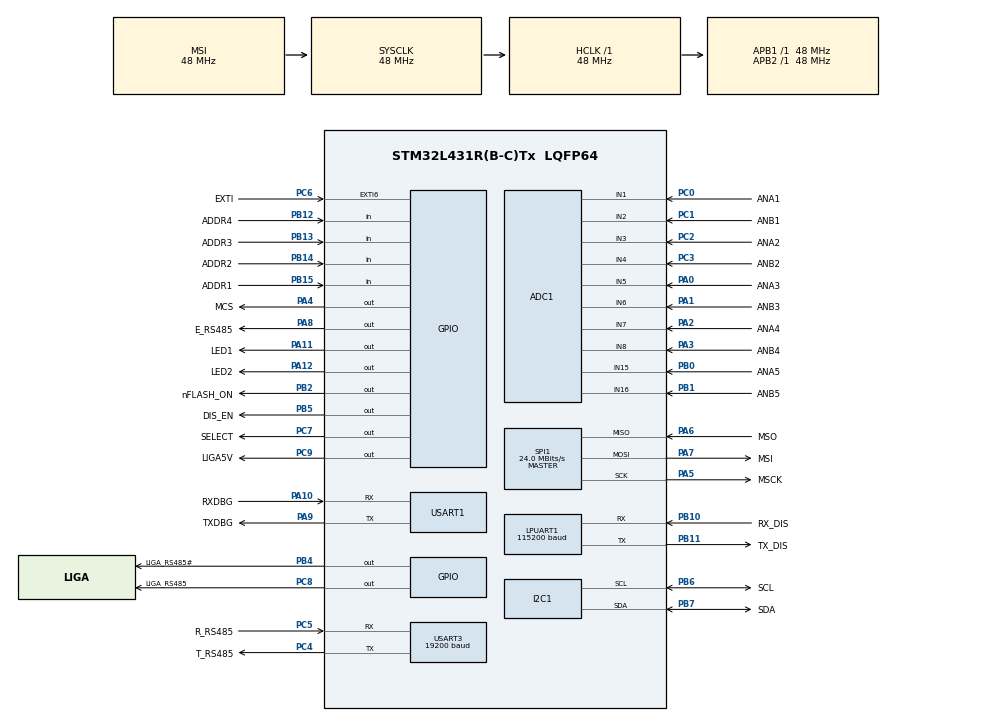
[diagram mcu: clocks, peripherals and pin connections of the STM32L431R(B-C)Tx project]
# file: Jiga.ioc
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ADC1.Channel-0\#ChannelRegularConversion=ADC_CHANNEL_16
ADC1.Channel-1\#ChannelRegularConversion=ADC_CHANNEL_15
ADC1.Channel-2\#ChannelRegularConversion=ADC_CHANNEL_8
ADC1.Channel-3\#ChannelRegularConversion=ADC_CHANNEL_7
ADC1.Channel-4\#ChannelRegularConversion=ADC_CHANNEL_6
ADC1.Channel-5\#ChannelRegularConversion=ADC_CHANNEL_5
ADC1.Channel-6\#ChannelRegularConversion=ADC_CHANNEL_4
ADC1.Channel-7\#ChannelRegularConversion=ADC_CHANNEL_3
ADC1.Channel-8\#ChannelRegularConversion=ADC_CHANNEL_2
ADC1.Channel-9\#ChannelRegularConversion=ADC_CHANNEL_1
ADC1.NbrOfConversion=10
ADC1.NbrOfConversionFlag=1
ADC1.OffsetNumber-0\#ChannelRegularConversion=ADC_OFFSET_NONE
ADC1.OffsetNumber-1\#ChannelRegularConversion=ADC_OFFSET_NONE
ADC1.OffsetNumber-2\#ChannelRegularConversion=ADC_OFFSET_NONE
ADC1.OffsetNumber-3\#ChannelRegularConversion=ADC_OFFSET_NONE
ADC1.OffsetNumber-4\#ChannelRegularConversion=ADC_OFFSET_NONE
ADC1.OffsetNumber-5\#ChannelRegularConversion=ADC_OFFSET_NONE
ADC1.OffsetNumber-6\#ChannelRegularConversion=ADC_OFFSET_NONE
ADC1.OffsetNumber-7\#ChannelRegularConversion=ADC_OFFSET_NONE
ADC1.OffsetNumber-8\#ChannelRegularConversion=ADC_OFFSET_NONE
ADC1.OffsetNumber-9\#ChannelRegularConversion=ADC_OFFSET_NONE
ADC1.Rank-0\#ChannelRegularConversion=1
ADC1.Rank-1\#ChannelRegularConversion=2
ADC1.Rank-2\#ChannelRegularConversion=3
ADC1.Rank-3\#ChannelRegularConversion=4
ADC1.Rank-4\#ChannelRegularConversion=5
ADC1.Rank-5\#ChannelRegularConversion=6
ADC1.Rank-6\#ChannelRegularConversion=7
ADC1.Rank-7\#ChannelRegularConversion=8
ADC1.Rank-8\#ChannelRegularConversion=9
ADC1.Rank-9\#ChannelRegularConversion=10
ADC1.SamplingTime-0\#ChannelRegularConversion=ADC_SAMPLETIME_12CYCLES_5
ADC1.SamplingTime-1\#ChannelRegularConversion=ADC_SAMPLETIME_12CYCLES_5
ADC1.SamplingTime-2\#ChannelRegularConversion=ADC_SAMPLETIME_12CYCLES_5
ADC1.SamplingTime-3\#ChannelRegularConversion=ADC_SAMPLETIME_12CYCLES_5
ADC1.SamplingTime-4\#ChannelRegularConversion=ADC_SAMPLETIME_12CYCLES_5
ADC1.SamplingTime-5\#ChannelRegularConversion=ADC_SAMPLETIME_12CYCLES_5
ADC1.SamplingTime-6\#ChannelRegularConversion=ADC_SAMPLETIME_12CYCLES_5
ADC1.SamplingTime-7\#ChannelRegularConversion=ADC_SAMPLETIME_12CYCLES_5
ADC1.SamplingTime-8\#ChannelRegularConversion=ADC_SAMPLETIME_12CYCLES_5
ADC1.SamplingTime-9\#ChannelRegularConversion=ADC_SAMPLETIME_12CYCLES_5
ADC1.master=1
CRC.CRCLength=CRC_POLYLENGTH_16B
CRC.DefaultInitValueUse=DEFAULT_INIT_VALUE_DISABLE
CRC.DefaultPolynomialUse=DEFAULT_POLYNOMIAL_DISABLE
CRC.GeneratingPolynomial=X15+X2+X0
CRC.InitValue=65535
CRC.InputDataInversionMode=CRC_INPUTDATA_INVERSION_BYTE
CRC.OutputDataInversionMode=CRC_OUTPUTDATA_INVERSION_ENABLE
Dma.ADC1.0.Direction=DMA_PERIPH_TO_MEMORY
Dma.ADC1.0.Instance=DMA1_Channel1
Dma.ADC1.0.MemDataAlignment=DMA_MDATAALIGN_HALFWORD
Dma.ADC1.0.MemInc=DMA_MINC_ENABLE
Dma.ADC1.0.Mode=DMA_NORMAL
Dma.ADC1.0.PeriphDataAlignment=DMA_PDATAALIGN_HALFWORD
Dma.ADC1.0.PeriphInc=DMA_PINC_DISABLE
Dma.ADC1.0.Priority=DMA_PRIORITY_LOW
Dma.Request0=ADC1
I2C1.Timing=0x10805D88
IWDG.Prescaler=IWDG_PRESCALER_32
IWDG.Reload=2000
IWDG.Window=2000
LPUART1.BaudRate=115200
LPUART1.WordLength=UART_WORDLENGTH_8B
Mcu.Family=STM32L4
Mcu.Name=STM32L431R(B-C)Tx
Mcu.Package=LQFP64
NVIC.DMA1_Channel1_IRQn=true\:0\:0\:false\:false\:true\:false\:true\:true
NVIC.EXTI9_5_IRQn=true\:0\:0\:false\:false\:true\:true\:true\:true
NVIC.LPUART1_IRQn=true\:0\:0\:true\:false\:true\:true\:true\:true
NVIC.PriorityGroup=NVIC_PRIORITYGROUP_4
NVIC.RTC_WKUP_IRQn=true\:3\:0\:true\:false\:true\:true\:true\:true
NVIC.TIM6_DAC_IRQn=true\:1\:0\:true\:false\:true\:true\:true\:true
NVIC.USART1_IRQn=true\:2\:0\:true\:false\:true\:true\:true\:true
NVIC.USART3_IRQn=true\:2\:0\:true\:false\:true\:true\:true\:true
PA0.GPIO_Label=ANA3
PA0.Signal=ADCx_IN5
PA1.GPIO_Label=ANB3
PA1.Signal=ADCx_IN6
PA10.GPIO_Label=RXDBG
PA10.Mode=Asynchronous
PA10.Signal=USART1_RX
PA11.GPIO_Label=LED1
PA11.Signal=GPIO_Output
PA12.GPIO_Label=LED2
PA12.Signal=GPIO_Output
PA13\ (JTMS-SWDIO).Mode=Serial_Wire
PA13\ (JTMS-SWDIO).Signal=SYS_JTMS-SWDIO
PA14\ (JTCK-SWCLK).Mode=Serial_Wire
PA14\ (JTCK-SWCLK).Signal=SYS_JTCK-SWCLK
PA2.GPIO_Label=ANA4
PA2.Signal=ADCx_IN7
PA3.GPIO_Label=ANB4
PA3.Signal=ADCx_IN8
PA4.GPIO_Label=MCS
PA4.GPIO_PuPd=GPIO_NOPULL
PA4.Signal=GPIO_Output
PA5.GPIO_Label=MSCK
PA5.Mode=Full_Duplex_Master
PA5.Signal=SPI1_SCK
PA6.GPIO_Label=MSO
PA6.Mode=Full_Duplex_Master
PA6.Signal=SPI1_MISO
PA7.GPIO_Label=MSI
PA7.Mode=Full_Duplex_Master
PA7.Signal=SPI1_MOSI
PA8.GPIO_Label=E_RS485
PA8.Signal=GPIO_Output
PA9.GPIO_Label=TXDBG
PA9.Mode=Asynchronous
PA9.Signal=USART1_TX
PB0.GPIO_Label=ANA5
PB0.Signal=ADCx_IN15
PB1.GPIO_Label=ANB5
PB1.Signal=ADCx_IN16
PB10.GPIO_Label=RX_DIS
PB10.Mode=Asynchronous
PB10.Signal=LPUART1_RX
PB11.GPIO_Label=TX_DIS
PB11.Mode=Asynchronous
PB11.Signal=LPUART1_TX
PB12.GPIO_Label=ADDR4
PB12.Signal=GPIO_Input
PB13.GPIO_Label=ADDR3
PB13.Signal=GPIO_Input
PB14.GPIO_Label=ADDR2
PB14.Signal=GPIO_Input
PB15.GPIO_Label=ADDR1
PB15.Signal=GPIO_Input
PB2.GPIO_Label=nFLASH_ON
PB2.Signal=GPIO_Output
PB4\ (NJTRST).GPIO_Label=LIGA_RS485\#
PB4\ (NJTRST).GPIO_PuPd=GPIO_PULLUP
PB4\ (NJTRST).Signal=GPIO_Output
PB5.GPIO_Label=DIS_EN
PB5.GPIO_PuPd=GPIO_PULLDOWN
PB5.Signal=GPIO_Output
PB6.GPIO_Label=SCL
PB6.Mode=I2C
PB6.Signal=I2C1_SCL
PB7.GPIO_Label=SDA
PB7.Mode=I2C
PB7.Signal=I2C1_SDA
PC0.GPIO_Label=ANA1
PC0.Signal=ADCx_IN1
PC1.GPIO_Label=ANB1
PC1.Signal=ADCx_IN2
PC14-OSC32_IN\ (PC14).Mode=LSE-External-Oscillator
PC14-OSC32_IN\ (PC14).Signal=RCC_OSC32_IN
PC15-OSC32_OUT\ (PC15).Mode=LSE-External-Oscillator
PC15-OSC32_OUT\ (PC15).Signal=RCC_OSC32_OUT
PC2.GPIO_Label=ANA2
PC2.Signal=ADCx_IN3
PC3.GPIO_Label=ANB2
PC3.Signal=ADCx_IN4
PC4.GPIO_Label=T_RS485
PC4.GPIO_PuPd=GPIO_NOPULL
PC4.Mode=Asynchronous
PC4.Signal=USART3_TX
PC5.GPIO_Label=R_RS485
PC5.GPIO_PuPd=GPIO_NOPULL
PC5.Mode=Asynchronous
PC5.Signal=USART3_RX
PC6.GPIO_Label=EXTI
PC6.GPIO_ModeDefaultEXTI=GPIO_MODE_IT_FALLING
PC6.GPIO_PuPd=GPIO_NOPULL
PC6.Signal=GPXTI6
PC7.GPIO_Label=SELECT
PC7.Signal=GPIO_Output
PC8.GPIO_Label=LIGA_RS485
PC8.Signal=GPIO_Output
PC9.GPIO_Label=LIGA5V
PC9.Signal=GPIO_Output
PH0-OSC_IN\ (PH0).Mode=HSE-External-Oscillator
PH0-OSC_IN\ (PH0).Signal=RCC_OSC_IN
PH1-OSC_OUT\ (PH1).Mode=HSE-External-Oscillator
PH1-OSC_OUT\ (PH1).Signal=RCC_OSC_OUT
ProjectManager.HeapSize=0x200
ProjectManager.StackSize=0x400
ProjectManager.TargetToolchain=STM32CubeIDE
RCC.ADCCLockSelection=RCC_ADCCLKSOURCE_SYSCLK
RCC.ADCFreq_Value=48000000
RCC.AHBFreq_Value=48000000
RCC.APB1Freq_Value=48000000
RCC.APB1TimFreq_Value=48000000
RCC.APB2Freq_Value=48000000
RCC.APB2TimFreq_Value=48000000
RCC.CortexFreq_Value=48000000
RCC.HCLKFreq_Value=48000000
RCC.HSE_VALUE=8000000
RCC.HSI48_VALUE=48000000
RCC.HSI_VALUE=16000000
RCC.MSIClockRange=RCC_MSIRANGE_11
RCC.MSI_VALUE=48000000
RCC.PLLSAI1N=12
RCC.PLLSourceVirtual=RCC_PLLSOURCE_HSE
RCC.SYSCLKFreq_VALUE=48000000
RCC.VCOOutputFreq_Value=64000000
RTC.Format=RTC_FORMAT_BIN
RTC.WakeUpCounter-WakeUp=2000
SH.ADCx_IN1.0=ADC1_IN1,IN1-Single-Ended
SH.ADCx_IN15.0=ADC1_IN15,IN15-Single-Ended
SH.ADCx_IN16.0=ADC1_IN16,IN16-Single-Ended
SH.ADCx_IN2.0=ADC1_IN2,IN2-Single-Ended
SH.ADCx_IN3.0=ADC1_IN3,IN3-Single-Ended
SH.ADCx_IN4.0=ADC1_IN4,IN4-Single-Ended
SH.ADCx_IN5.0=ADC1_IN5,IN5-Single-Ended
SH.ADCx_IN6.0=ADC1_IN6,IN6-Single-Ended
SH.ADCx_IN7.0=ADC1_IN7,IN7-Single-Ended
SH.ADCx_IN8.0=ADC1_IN8,IN8-Single-Ended
SPI1.CalculateBaudRate=24.0 MBits/s
SPI1.DataSize=SPI_DATASIZE_8BIT
SPI1.Direction=SPI_DIRECTION_2LINES
SPI1.Mode=SPI_MODE_MASTER
SPI1.VirtualType=VM_MASTER
TIM6.AutoReloadPreload=TIM_AUTORELOAD_PRELOAD_ENABLE
TIM6.Period=999
TIM6.Prescaler=48
USART1.VirtualMode-Asynchronous=VM_ASYNC
USART3.BaudRate=19200
USART3.MSBFirstParam=ADVFEATURE_MSBFIRST_DISABLE
USART3.VirtualMode-Asynchronous=VM_ASYNC
VP_CRC_VS_CRC.Mode=CRC_Activate
VP_IWDG_VS_IWDG.Mode=IWDG_Activate
VP_RTC_VS_RTC_Activate.Mode=RTC_Enabled
VP_RTC_VS_RTC_Calendar.Mode=RTC_Calendar
VP_RTC_VS_RTC_WakeUp_intern.Mode=WakeUp
VP_TIM6_VS_ClockSourceINT.Mode=Enable_Timer
board=custom

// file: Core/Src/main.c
/* USER CODE BEGIN Header */
/**
  ******************************************************************************
  * @file           : main.c
  * @brief          : Main program body
  ******************************************************************************
  * @attention
  *
  * Copyright (c) 2025 STMicroelectronics.
  * All rights reserved.
  *
  * This software is licensed under terms that can be found in the LICENSE file
  * in the root directory of this software component.
  * If no LICENSE file comes with this software, it is provided AS-IS.
  *
  ******************************************************************************
  */
/* USER CODE END Header */
#include "main.h"
#include "adc.h"
#include "crc.h"
#include "dma.h"
#include "i2c.h"
#include "iwdg.h"
#include "usart.h"
#include "rtc.h"
#include "spi.h"
#include "tim.h"
#include "gpio.h"

/* USER CODE BEGIN Includes */
#include "app.h"
/* USER CODE END Includes */

void SystemClock_Config(void);

int main(void)
{

  /* MCU Configuration--------------------------------------------------------*/

  /* Reset of all peripherals, Initializes the Flash interface and the Systick. */
  HAL_Init();

  /* Configure the system clock */
  SystemClock_Config();

  /* Initialize all configured peripherals */
  MX_GPIO_Init();
  MX_DMA_Init();
  MX_ADC1_Init();
  MX_I2C1_Init();
  MX_LPUART1_UART_Init();
  MX_USART1_UART_Init();
  MX_USART3_UART_Init();
  MX_SPI1_Init();
  MX_TIM6_Init();
  MX_CRC_Init();
  MX_RTC_Init();
  MX_IWDG_Init();
  /* USER CODE BEGIN 2 */
  __disable_irq();
  APP_init();
  __enable_irq();
  /* USER CODE END 2 */

  /* Infinite loop */
  /* USER CODE BEGIN WHILE */
  while (1)
  {
      HAL_IWDG_Refresh(&hiwdg);
      APP_poll();
    /* USER CODE END WHILE */

  }
}

void SystemClock_Config(void)
{
  RCC_OscInitTypeDef RCC_OscInitStruct = {0};
  RCC_ClkInitTypeDef RCC_ClkInitStruct = {0};

  /** Configure the main internal regulator output voltage
  */
  if (HAL_PWREx_ControlVoltageScaling(PWR_REGULATOR_VOLTAGE_SCALE1) != HAL_OK)
  {
    Error_Handler();
  }

  /** Configure LSE Drive Capability
  */
  HAL_PWR_EnableBkUpAccess();
  __HAL_RCC_LSEDRIVE_CONFIG(RCC_LSEDRIVE_LOW);

  /** Initializes the RCC Oscillators according to the specified parameters
  * in the RCC_OscInitTypeDef structure.
  */
  RCC_OscInitStruct.OscillatorType = RCC_OSCILLATORTYPE_LSI|RCC_OSCILLATORTYPE_LSE
                              |RCC_OSCILLATORTYPE_MSI;
  RCC_OscInitStruct.LSEState = RCC_LSE_ON;
  RCC_OscInitStruct.LSIState = RCC_LSI_ON;
  RCC_OscInitStruct.MSIState = RCC_MSI_ON;
  RCC_OscInitStruct.MSICalibrationValue = 0;
  RCC_OscInitStruct.MSIClockRange = RCC_MSIRANGE_11;
  RCC_OscInitStruct.PLL.PLLState = RCC_PLL_NONE;
  if (HAL_RCC_OscConfig(&RCC_OscInitStruct) != HAL_OK)
  {
    Error_Handler();
  }

  /** Initializes the CPU, AHB and APB buses clocks
  */
  RCC_ClkInitStruct.ClockType = RCC_CLOCKTYPE_HCLK|RCC_CLOCKTYPE_SYSCLK
                              |RCC_CLOCKTYPE_PCLK1|RCC_CLOCKTYPE_PCLK2;
  RCC_ClkInitStruct.SYSCLKSource = RCC_SYSCLKSOURCE_MSI;
  RCC_ClkInitStruct.AHBCLKDivider = RCC_SYSCLK_DIV1;
  RCC_ClkInitStruct.APB1CLKDivider = RCC_HCLK_DIV1;
  RCC_ClkInitStruct.APB2CLKDivider = RCC_HCLK_DIV1;

  if (HAL_RCC_ClockConfig(&RCC_ClkInitStruct, FLASH_LATENCY_2) != HAL_OK)
  {
    Error_Handler();
  }

  /** Enable MSI Auto calibration
  */
  HAL_RCCEx_EnableMSIPLLMode();
}

void Error_Handler(void)
{
  __disable_irq();
  while (1)
  {
  }
}
